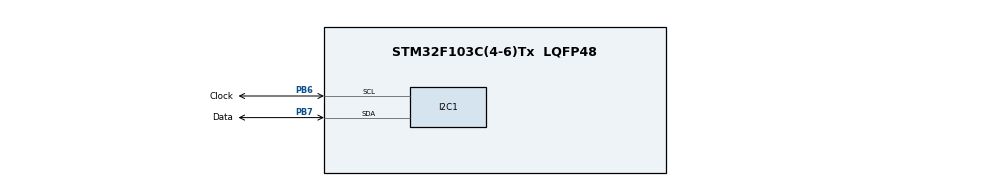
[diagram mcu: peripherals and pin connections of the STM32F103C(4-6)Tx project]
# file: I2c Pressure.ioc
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Mcu.Family=STM32F1
Mcu.Name=STM32F103C(4-6)Tx
Mcu.Package=LQFP48
NVIC.PriorityGroup=NVIC_PRIORITYGROUP_4
PA13.Mode=Serial_Wire
PA13.Signal=SYS_JTMS-SWDIO
PA14.Mode=Serial_Wire
PA14.Signal=SYS_JTCK-SWCLK
PB6.GPIO_Label=Clock
PB6.GPIO_Pu=GPIO_PULLUP
PB6.Mode=I2C
PB6.Signal=I2C1_SCL
PB7.GPIO_Label=Data
PB7.GPIO_Pu=GPIO_PULLUP
PB7.Mode=I2C
PB7.Signal=I2C1_SDA
PD0-OSC_IN.Mode=HSE-External-Oscillator
PD0-OSC_IN.Signal=RCC_OSC_IN
PD1-OSC_OUT.Mode=HSE-External-Oscillator
PD1-OSC_OUT.Signal=RCC_OSC_OUT
ProjectManager.HeapSize=0x200
ProjectManager.StackSize=0x400
ProjectManager.TargetToolchain=STM32CubeIDE
RCC.APB1Freq_Value=8000000
RCC.APB2Freq_Value=8000000
board=custom

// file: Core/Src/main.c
/* USER CODE BEGIN Header */
/**
  ******************************************************************************
  * @file           : main.c
  * @brief          : Main program body
  ******************************************************************************
  * @attention
  *
  * Copyright (c) 2025 STMicroelectronics.
  * All rights reserved.
  *
  * This software is licensed under terms that can be found in the LICENSE file
  * in the root directory of this software component.
  * If no LICENSE file comes with this software, it is provided AS-IS.
  *
  ******************************************************************************
  */
/* USER CODE END Header */
#include "main.h"

/* USER CODE BEGIN Includes */
#include <stdio.h>
#include<stdlib.h>

/* USER CODE END Includes */

/* USER CODE BEGIN PM */
#define BMP_DEV_ADDR 0X76<<1
#define BMP_PRESSURE_REG 0XF7
#define BMP_RESET_REG 0XE0
#define BMP_CTRL_MSG 0xF4
#define BMP_CONFIG_REG 0XF5
#define BMP_RESET_VALUE 0XB6

/* USER CODE END PM */

I2C_HandleTypeDef hi2c1;

void SystemClock_Config(void);
static void MX_GPIO_Init(void);
static void MX_I2C1_Init(void);

/* USER CODE BEGIN 0 */
void BMP_INIT(void){
	uint8_t config[2];

	config[0] = BMP_RESET_REG;
	config[1] = BMP_RESET_VALUE;
	HAL_I2C_Master_Transmit(&hi2c1, BMP_DEV_ADDR, config, 2, HAL_MAX_DELAY);
	HAL_Delay(10);

	config[0] = BMP_CTRL_MSG;
	config[1] = 0x27;
	HAL_I2C_Master_Transmit(&hi2c1, BMP_DEV_ADDR, config, 2, HAL_MAX_DELAY);

	config[0] = BMP_CONFIG_REG;
	config[1] = 0xA0;
	HAL_I2C_Master_Transmit(&hi2c1, BMP_DEV_ADDR, config, 2, HAL_MAX_DELAY);
}

uint32_t BMP_readpressure(){
	uint8_t data[3];
	uint32_t pressure,presssure_pa;

	HAL_I2C_Mem_Read(&hi2c1, BMP_DEV_ADDR, BMP_PRESSURE_REG, I2C_MEMADD_SIZE_8BIT, data, 3, HAL_MAX_DELAY);

	pressure = (uint32_t)data[0]<<12 | (uint32_t)data[1]<<4 | data[2]>>4;

	presssure_pa = pressure/16;

	return presssure_pa;
}
/* USER CODE END 0 */

int main(void)
{

  /* MCU Configuration--------------------------------------------------------*/

  /* Reset of all peripherals, Initializes the Flash interface and the Systick. */
  HAL_Init();

  /* Configure the system clock */
  SystemClock_Config();

  /* Initialize all configured peripherals */
  MX_GPIO_Init();
  MX_I2C1_Init();
  /* USER CODE BEGIN 2 */
  BMP_INIT();

  /* USER CODE END 2 */

  /* Infinite loop */
  while (1)
  {
	  	  uint32_t pressure_val = BMP_readpressure();
	  	  printf("Pressure: %ld Pa\n",pressure_val);
	  	  HAL_Delay(1000);

  }
}

void SystemClock_Config(void)
{
  RCC_OscInitTypeDef RCC_OscInitStruct = {0};
  RCC_ClkInitTypeDef RCC_ClkInitStruct = {0};

  /** Initializes the RCC Oscillators according to the specified parameters
  * in the RCC_OscInitTypeDef structure.
  */
  RCC_OscInitStruct.OscillatorType = RCC_OSCILLATORTYPE_HSI;
  RCC_OscInitStruct.HSIState = RCC_HSI_ON;
  RCC_OscInitStruct.HSICalibrationValue = RCC_HSICALIBRATION_DEFAULT;
  RCC_OscInitStruct.PLL.PLLState = RCC_PLL_NONE;
  if (HAL_RCC_OscConfig(&RCC_OscInitStruct) != HAL_OK)
  {
    Error_Handler();
  }

  /** Initializes the CPU, AHB and APB buses clocks
  */
  RCC_ClkInitStruct.ClockType = RCC_CLOCKTYPE_HCLK|RCC_CLOCKTYPE_SYSCLK
                              |RCC_CLOCKTYPE_PCLK1|RCC_CLOCKTYPE_PCLK2;
  RCC_ClkInitStruct.SYSCLKSource = RCC_SYSCLKSOURCE_HSI;
  RCC_ClkInitStruct.AHBCLKDivider = RCC_SYSCLK_DIV1;
  RCC_ClkInitStruct.APB1CLKDivider = RCC_HCLK_DIV1;
  RCC_ClkInitStruct.APB2CLKDivider = RCC_HCLK_DIV1;

  if (HAL_RCC_ClockConfig(&RCC_ClkInitStruct, FLASH_LATENCY_0) != HAL_OK)
  {
    Error_Handler();
  }
}

static void MX_I2C1_Init(void)
{

  hi2c1.Instance = I2C1;
  hi2c1.Init.ClockSpeed = 100000;
  hi2c1.Init.DutyCycle = I2C_DUTYCYCLE_2;
  hi2c1.Init.OwnAddress1 = 0;
  hi2c1.Init.AddressingMode = I2C_ADDRESSINGMODE_7BIT;
  hi2c1.Init.DualAddressMode = I2C_DUALADDRESS_DISABLE;
  hi2c1.Init.OwnAddress2 = 0;
  hi2c1.Init.GeneralCallMode = I2C_GENERALCALL_DISABLE;
  hi2c1.Init.NoStretchMode = I2C_NOSTRETCH_DISABLE;
  if (HAL_I2C_Init(&hi2c1) != HAL_OK)
  {
    Error_Handler();
  }

}

static void MX_GPIO_Init(void)
{

  /* GPIO Ports Clock Enable */
  __HAL_RCC_GPIOD_CLK_ENABLE();
  __HAL_RCC_GPIOA_CLK_ENABLE();
  __HAL_RCC_GPIOB_CLK_ENABLE();

}

void Error_Handler(void)
{
  __disable_irq();
  while (1)
  {
  }
}
